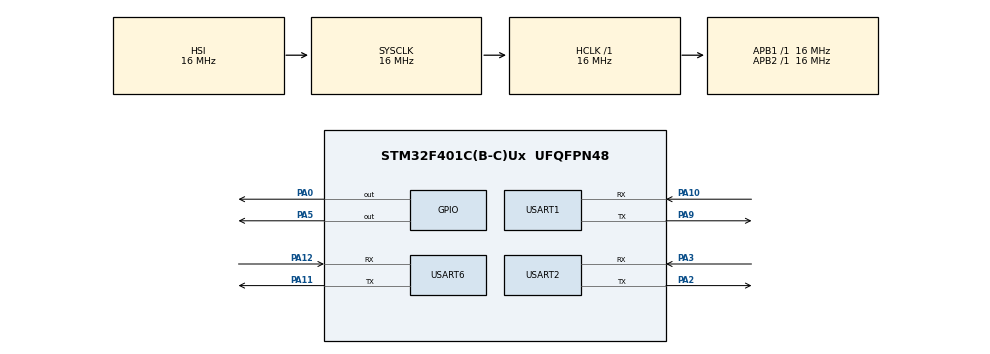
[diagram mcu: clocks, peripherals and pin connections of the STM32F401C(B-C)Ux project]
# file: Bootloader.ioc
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Mcu.Family=STM32F4
Mcu.Name=STM32F401C(B-C)Ux
Mcu.Package=UFQFPN48
NVIC.PriorityGroup=NVIC_PRIORITYGROUP_4
PA0-WKUP.Signal=GPIO_Output
PA10.Mode=Asynchronous
PA10.Signal=USART1_RX
PA11.Mode=Asynchronous
PA11.Signal=USART6_TX
PA12.Mode=Asynchronous
PA12.Signal=USART6_RX
PA13.Mode=Serial_Wire
PA13.Signal=SYS_JTMS-SWDIO
PA14.Mode=Serial_Wire
PA14.Signal=SYS_JTCK-SWCLK
PA2.Mode=Asynchronous
PA2.Signal=USART2_TX
PA3.Mode=Asynchronous
PA3.Signal=USART2_RX
PA5.Signal=GPIO_Output
PA9.Mode=Asynchronous
PA9.Signal=USART1_TX
PH0\ -\ OSC_IN.Mode=HSE-External-Oscillator
PH0\ -\ OSC_IN.Signal=RCC_OSC_IN
PH1\ -\ OSC_OUT.Mode=HSE-External-Oscillator
PH1\ -\ OSC_OUT.Signal=RCC_OSC_OUT
ProjectManager.HeapSize=0x200
ProjectManager.StackSize=0x400
ProjectManager.TargetToolchain=STM32CubeIDE
RCC.48MHZClocksFreq_Value=75000000
RCC.AHBFreq_Value=16000000
RCC.APB1Freq_Value=16000000
RCC.APB2Freq_Value=16000000
RCC.CortexFreq_Value=16000000
RCC.HSE_VALUE=25000000
RCC.HSI_VALUE=16000000
RCC.LSE_VALUE=32768
RCC.PLLSourceVirtual=RCC_PLLSOURCE_HSE
RCC.SYSCLKFreq_VALUE=16000000
RCC.VCOOutputFreq_Value=300000000
USART1.VirtualMode=VM_ASYNC
USART2.VirtualMode=VM_ASYNC
USART6.VirtualMode=VM_ASYNC
VP_CRC_VS_CRC.Mode=CRC_Activate
board=custom

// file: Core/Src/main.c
/* USER CODE BEGIN Header */
/**
 ******************************************************************************
 * @file           : main.c
 * @brief          : Main program body
 ******************************************************************************
 * @attention
 *
 * Copyright (c) 2024 STMicroelectronics.
 * All rights reserved.
 *
 * This software is licensed under terms that can be found in the LICENSE file
 * in the root directory of this software component.
 * If no LICENSE file comes with this software, it is provided AS-IS.
 *
 ******************************************************************************
 */
/* USER CODE END Header */
#include "main.h"
#include "crc.h"
#include "usart.h"
#include "gpio.h"

/* USER CODE BEGIN Includes */
#include "Bootloader_Interface.h"
#include "Bootloader_Config.h"
#include "Bootloader_Private.h"
/* USER CODE END Includes */

void SystemClock_Config(void);

int main(void)
{
	/* USER CODE BEGIN 1 */
	//HAL_GPIO_WritePin(GPIOA, GPIO_PIN_0, GPIO_PIN_RESET);
	/* USER CODE END 1 */

	/* MCU Configuration--------------------------------------------------------*/

	/* Reset of all peripherals, Initializes the Flash interface and the Systick. */
	HAL_Init();

	/* Configure the system clock */
	SystemClock_Config();

	/* Initialize all configured peripherals */
	MX_GPIO_Init();
	MX_USART1_UART_Init();
	MX_USART2_UART_Init();
	MX_CRC_Init();
	MX_USART6_UART_Init();

	/* Infinite loop */
	while (1)
	{

		/* USER CODE BEGIN 3 */
		BL_FeatchHostCommand();
		/* USER CODE END 3 */
	}
}
void SystemClock_Config(void)
{
	RCC_OscInitTypeDef RCC_OscInitStruct = {0};
	RCC_ClkInitTypeDef RCC_ClkInitStruct = {0};

	/** Configure the main internal regulator output voltage
	 */
	__HAL_RCC_PWR_CLK_ENABLE();
	__HAL_PWR_VOLTAGESCALING_CONFIG(PWR_REGULATOR_VOLTAGE_SCALE2);

	/** Initializes the RCC Oscillators according to the specified parameters
	 * in the RCC_OscInitTypeDef structure.
	 */
	RCC_OscInitStruct.OscillatorType = RCC_OSCILLATORTYPE_HSI;
	RCC_OscInitStruct.HSIState = RCC_HSI_ON;
	RCC_OscInitStruct.HSICalibrationValue = RCC_HSICALIBRATION_DEFAULT;
	RCC_OscInitStruct.PLL.PLLState = RCC_PLL_NONE;
	if (HAL_RCC_OscConfig(&RCC_OscInitStruct) != HAL_OK)
	{
		Error_Handler();
	}

	/** Initializes the CPU, AHB and APB buses clocks
	 */
	RCC_ClkInitStruct.ClockType = RCC_CLOCKTYPE_HCLK|RCC_CLOCKTYPE_SYSCLK
			|RCC_CLOCKTYPE_PCLK1|RCC_CLOCKTYPE_PCLK2;
	RCC_ClkInitStruct.SYSCLKSource = RCC_SYSCLKSOURCE_HSI;
	RCC_ClkInitStruct.AHBCLKDivider = RCC_SYSCLK_DIV1;
	RCC_ClkInitStruct.APB1CLKDivider = RCC_HCLK_DIV1;
	RCC_ClkInitStruct.APB2CLKDivider = RCC_HCLK_DIV1;

	if (HAL_RCC_ClockConfig(&RCC_ClkInitStruct, FLASH_LATENCY_0) != HAL_OK)
	{
		Error_Handler();
	}
}

void Error_Handler(void)
{
	__disable_irq();
	while (1)
	{
	}
}
